# PIC16LF1777 register map
Vendor: Microchip
Registers are 8-bit, read-write, reset 0x0 unless marked. A register's access mark holds for its fields unless they carry their own. Addresses are absolute, and some are shared; only a register's first bit layout is shown; [hi:lo] are bit positions; 'fields as' and 'values as' point back to an identical list.

## pwm
0x614 PWM3DCL reset not defined — (power-on value xx------)
  [7:6] DC
0x615 PWM3DCH reset not defined — (power-on value xxxxxxxx)
  [7:0] DC
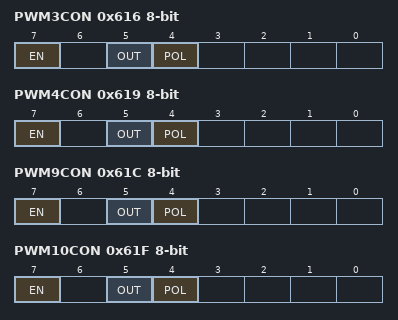
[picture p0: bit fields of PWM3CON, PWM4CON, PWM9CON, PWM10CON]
0x616 PWM3CON
  [7] EN, [5] OUT ro, [4] POL
0x617 PWM4DCL reset not defined — (power-on value xx------)
  [7:6] DC
0x618 PWM4DCH reset not defined — (power-on value xxxxxxxx)
  [7:0] DC
0x619 PWM4CON
  [7] EN, [5] OUT ro, [4] POL
0x61A PWM9DCL reset not defined — (power-on value xx------)
  [7:6] DC
0x61B PWM9DCH reset not defined — (power-on value xxxxxxxx)
  [7:0] DC
0x61C PWM9CON
  [7] EN, [5] OUT ro, [4] POL
0x61D PWM10DCL reset not defined — (power-on value xx------)
  [7:6] DC
0x61E PWM10DCH reset not defined — (power-on value xxxxxxxx)
  [7:0] DC
0x61F PWM10CON
  [7] EN, [5] OUT ro, [4] POL
0xD91 PWM5PHL reset not defined — 8-bit period timer (power-on value xxxxxxxx)
  [7:0] PH
0xD92 PWM5PHH reset not defined — (power-on value xxxxxxxx)
  [7:0] PH
0xD93 PWM5DCL reset not defined — (power-on value xxxxxxxx)
  [7:0] DC
0xD94 PWM5DCH reset not defined — (power-on value xxxxxxxx)
  [7:0] DC
0xD95 PWM5PRL reset not defined — (power-on value xxxxxxxx)
  [7:0] PR
0xD96 PWM5PRH reset not defined — (power-on value xxxxxxxx)
  [7:0] PR
0xD97 PWM5OFL reset not defined — (power-on value xxxxxxxx)
  [7:0] OF
0xD98 PWM5OFH reset not defined — (power-on value xxxxxxxx)
  [7:0] OF
0xD99 PWM5TMRL
  [7:0] TMR
0xD9A PWM5TMRH
  [7:0] TMR
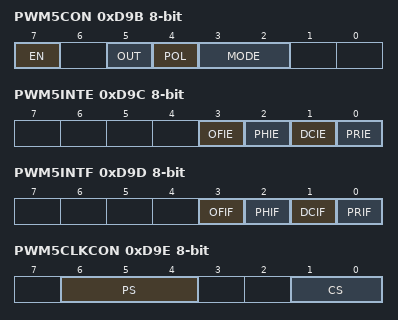
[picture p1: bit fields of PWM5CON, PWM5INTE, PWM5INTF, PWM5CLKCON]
0xD9B PWM5CON
  [7] EN, [5] OUT ro, [4] POL, [3:2] MODE
0xD9C PWM5INTE
  [3] OFIE, [2] PHIE, [1] DCIE, [0] PRIE
0xD9D PWM5INTF
  [3] OFIF — (can only be cleared)
  [2] PHIF — (can only be cleared)
  [1] DCIF — (can only be cleared)
  [0] PRIF — (can only be cleared)
0xD9E PWM5CLKCON
  [6:4] PS, [1:0] CS
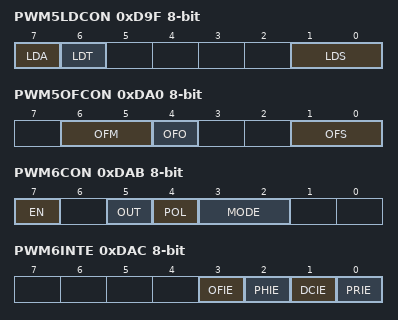
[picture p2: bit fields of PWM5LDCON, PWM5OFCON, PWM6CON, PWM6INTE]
0xD9F PWM5LDCON
  [7] LDA, [6] LDT, [1:0] LDS
0xDA0 PWM5OFCON
  [6:5] OFM, [4] OFO, [1:0] OFS
0xDA1 PWM6PHL reset not defined — 8-bit period timer (power-on value xxxxxxxx)
  [7:0] PH
0xDA2 PWM6PHH reset not defined — (power-on value xxxxxxxx)
  [7:0] PH
0xDA3 PWM6DCL reset not defined — (power-on value xxxxxxxx)
  [7:0] DC
0xDA4 PWM6DCH reset not defined — (power-on value xxxxxxxx)
  [7:0] DC
0xDA5 PWM6PRL reset not defined — (power-on value xxxxxxxx)
  [7:0] PR
0xDA6 PWM6PRH reset not defined — (power-on value xxxxxxxx)
  [7:0] PR
0xDA7 PWM6OFL reset not defined — (power-on value xxxxxxxx)
  [7:0] OF
0xDA8 PWM6OFH reset not defined — (power-on value xxxxxxxx)
  [7:0] OF
0xDA9 PWM6TMRL
  [7:0] TMR
0xDAA PWM6TMRH
  [7:0] TMR
0xDAB PWM6CON
  [7] EN, [5] OUT ro, [4] POL, [3:2] MODE
0xDAC PWM6INTE
  [3] OFIE, [2] PHIE, [1] DCIE, [0] PRIE
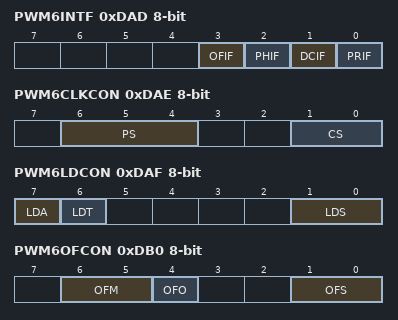
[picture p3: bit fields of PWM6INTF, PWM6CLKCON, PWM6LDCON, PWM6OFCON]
0xDAD PWM6INTF
  fields as PWM5INTF
0xDAE PWM6CLKCON
  [6:4] PS, [1:0] CS
0xDAF PWM6LDCON
  [7] LDA, [6] LDT, [1:0] LDS
0xDB0 PWM6OFCON
  [6:5] OFM, [4] OFO, [1:0] OFS
0xDB1 PWM11PHL reset not defined — 8-bit period timer (power-on value xxxxxxxx)
  [7:0] PH
0xDB2 PWM11PHH reset not defined — (power-on value xxxxxxxx)
  [7:0] PH
0xDB3 PWM11DCL reset not defined — (power-on value xxxxxxxx)
  [7:0] DC
0xDB4 PWM11DCH reset not defined — (power-on value xxxxxxxx)
  [7:0] DC
0xDB5 PWM11PRL reset not defined — (power-on value xxxxxxxx)
  [7:0] PR
0xDB6 PWM11PRH reset not defined — (power-on value xxxxxxxx)
  [7:0] PR
0xDB7 PWM11OFL reset not defined — (power-on value xxxxxxxx)
  [7:0] OF
0xDB8 PWM11OFH reset not defined — (power-on value xxxxxxxx)
  [7:0] OF
0xDB9 PWM11TMRL
  [7:0] TMR
0xDBA PWM11TMRH
  [7:0] TMR
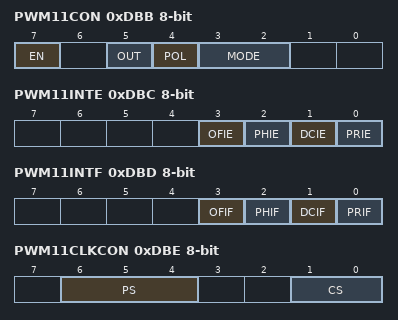
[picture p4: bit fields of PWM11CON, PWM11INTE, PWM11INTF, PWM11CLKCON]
0xDBB PWM11CON
  [7] EN, [5] OUT ro, [4] POL, [3:2] MODE
0xDBC PWM11INTE
  [3] OFIE, [2] PHIE, [1] DCIE, [0] PRIE
0xDBD PWM11INTF
  fields as PWM5INTF
0xDBE PWM11CLKCON
  [6:4] PS, [1:0] CS
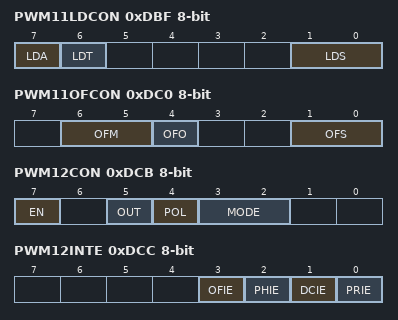
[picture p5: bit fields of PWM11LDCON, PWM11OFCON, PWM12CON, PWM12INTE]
0xDBF PWM11LDCON
  [7] LDA, [6] LDT, [1:0] LDS
0xDC0 PWM11OFCON
  [6:5] OFM, [4] OFO, [1:0] OFS
0xDC1 PWM12PHL reset not defined — 8-bit period timer (power-on value xxxxxxxx)
  [7:0] PH
0xDC2 PWM12PHH reset not defined — (power-on value xxxxxxxx)
  [7:0] PH
0xDC3 PWM12DCL reset not defined — (power-on value xxxxxxxx)
  [7:0] DC
0xDC4 PWM12DCH reset not defined — (power-on value xxxxxxxx)
  [7:0] DC
0xDC5 PWM12PRL reset not defined — (power-on value xxxxxxxx)
  [7:0] PR
0xDC6 PWM12PRH reset not defined — (power-on value xxxxxxxx)
  [7:0] PR
0xDC7 PWM12OFL reset not defined — (power-on value xxxxxxxx)
  [7:0] OF
0xDC8 PWM12OFH reset not defined — (power-on value xxxxxxxx)
  [7:0] OF
0xDC9 PWM12TMRL
  [7:0] TMR
0xDCA PWM12TMRH
  [7:0] TMR
0xDCB PWM12CON
  [7] EN, [5] OUT ro, [4] POL, [3:2] MODE
0xDCC PWM12INTE
  [3] OFIE, [2] PHIE, [1] DCIE, [0] PRIE
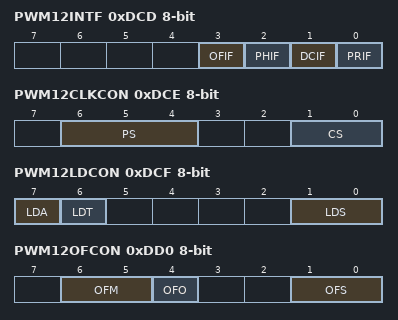
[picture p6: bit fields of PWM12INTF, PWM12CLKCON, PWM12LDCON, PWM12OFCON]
0xDCD PWM12INTF
  fields as PWM5INTF
0xDCE PWM12CLKCON
  [6:4] PS, [1:0] CS
0xDCF PWM12LDCON
  [7] LDA, [6] LDT, [1:0] LDS
0xDD0 PWM12OFCON
  [6:5] OFM, [4] OFO, [1:0] OFS
